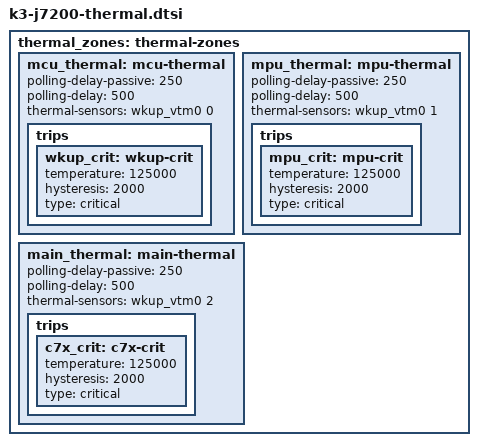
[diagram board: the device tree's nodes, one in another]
#include <dt-bindings/thermal/thermal.h>
thermal_zones: thermal-zones {
	mcu_thermal: mcu-thermal {
		polling-delay-passive = <250>;  
		polling-delay = <500>;  
		thermal-sensors = <&wkup_vtm0 0>;
		trips {
			wkup_crit: wkup-crit {
				temperature = <125000>;  
				hysteresis = <2000>;  
				type = "critical";
			};
		};
	};
	mpu_thermal: mpu-thermal {
		polling-delay-passive = <250>;  
		polling-delay = <500>;  
		thermal-sensors = <&wkup_vtm0 1>;
		trips {
			mpu_crit: mpu-crit {
				temperature = <125000>;  
				hysteresis = <2000>;  
				type = "critical";
			};
		};
	};
	main_thermal: main-thermal {
		polling-delay-passive = <250>;  
		polling-delay = <500>;  
		thermal-sensors = <&wkup_vtm0 2>;
		trips {
			c7x_crit: c7x-crit {
				temperature = <125000>;  
				hysteresis = <2000>;  
				type = "critical";
			};
		};
	};
};
